# iND83213A register map
Vendor: Indiemicro; Series: Rugby; File version: 1.0
High performance IC
CPU: CM0 r0p1, selectable endian, no MPU, no FPU, 4 interrupt priority bits
Registers are 32-bit, read-write, no defined reset value unless marked. A register's access mark holds for its fields unless they carry their own. Offsets are from the block's base; lines under a group give offsets from that group; [hi:lo] are bit positions; {n}, {i} and the like mark numbered series; 'fields as' and 'values as' point back to an identical list; <NAME> marks a mode.

## Memory map
0x50000000 CRGA size 0x40 — Clock & Reset Generator
0x50000040 PMUA size 0x20 — Power Management Unit
0x50000060 EVTHOLD size 0x20 — Event Hold Control
0x50000080 BTE size 0x80 — Block Transfer Engine registers
0x50010100 WICA size 0x100 — WakeUp Interrupt Controller
0x50010200 WDTA size 0x100 — Watchdog Timer Registers
0x50010300 LINS size 0x100 — LIN slave interface registers
0x50010400 LINM size 0x100 — LIN master interface registers
0x50010500 BUCK_INF size 0x100 — BUCK Interface Registers
0x50010600 SAR_CTRL size 0x100 — SAR ADC Interface registers
0x50010700 SPI size 0x100 — SPIM Interface registers
0x50010800 UART size 0x100 — UART Interface registers
0x50010900 PWM_AUX size 0x100 — Control (and status) registers for the pulse width modulation waveform generator.
0x50011000 PWM size 0x1000 — Control (and status) registers for the pulse width modulation waveform generator.
0x50012000 IOCTRLA size 0x1000 — I/O configuration and DFT pin control
0x50013000 SYSCTRLA size 0x1000 — System configuration and retention memory
0x50014000 GPIO size 0x1000 — GPIO bit control and configuration
0x50015000 PMUAPRE5V size 0x1000 — Power Management Unit of 5V domain
0x50020000 TIMER0 size 0x8 — General purpose timer 0 registers
0x50020008 TIMER1 size 0x8 — General purpose timer 1 registers
0x50020010 TIMER2 size 0x8 — General purpose timer 2 registers
0x50020018 WDT1 size 0x8 — The watchdog timer that is local to VERNE MCU
0x50020020 FLASH size 0x40 — FLASH Memory registers

## EVTHOLD — Event Hold Control
Base 0x50000060; register names take the prefix EVTHOLD_
0x00 HOLD
  [0] HOLD wo — Hold. Set to prevent serialisation of new non-wakeup events in prepartion for hibernate mode. At the point of becoming set, a request to send the lullaby interrupt is automatically generated. The lullaby handler can then safely assert the PMUA->CTRL.HIBERNATE bit in order to put the device into hibernate mode.

## BTE — Block Transfer Engine registers
Base 0x50000080; register names take the prefix BTE_
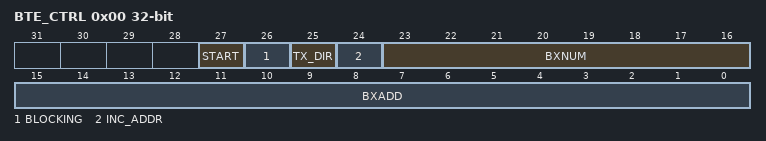
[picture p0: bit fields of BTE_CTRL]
0x00 BTE_CTRL — BTE Control Register
  [27] START — An operation is initiated when this bit is set. The bit auto-clears when the block is complete.
  [26] BLOCKING — If set then the block transfer has priority over the MCU. If the MCU tries to use the bus, it will stall until the block transfer is complete. If not set, then the MCU waits only until the remainder of the current word completes and then waits until the bus is idle again before continuing.
  [25] TX_DIR — Transfer direction. If set then SRAM->ASIC otherwise ASIC->SRAM
  [24] INC_ADDR — if set then ASIC die address increments at the end of each transfer. Set to zero if the peripheral is a FIFO.
  [23:16] BXNUM — Number of 32-bit words to transfer.
  [15:0] BXADD — Address of the ASIC die (LSB). This is the lower 16 bits of the ASIC die address. The MSBs are 0x5001.
0x04 BTE_SRAM_ADDR — BTE SRAM Address Register
  [15:0] BXSRAMADDR — Address of the SRAM (LSB). This is the lower 16 bits of the SRAM address. The MSBs are 0x2000.

## WICA — WakeUp Interrupt Controller
Base 0x50010100; register names take the prefix WICA_
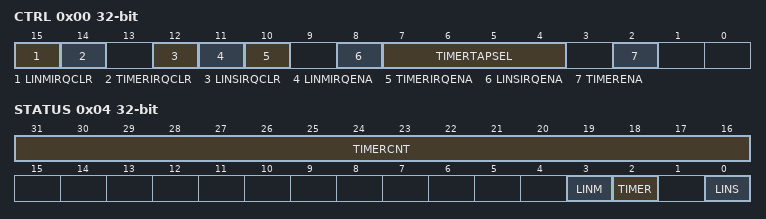
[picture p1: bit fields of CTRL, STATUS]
0x00 CTRL — Wakeup Control Register
  [15] LINMIRQCLR wo — clear the wulin_irq. writting a '1 to this register will clear the wulins_irq
  [14] TIMERIRQCLR wo — clear the wutimer_irq. writting a '1 to this register will clear the wutimer_irq
  [12] LINSIRQCLR wo — clear the wulin_irq. writting a '1 to this register will clear the wulins_irq
  [11] LINMIRQENA — LIN Master Wakeup Interrupt Enable. if set, wulinm_irq is asserted if a wakeup signal is detected on the LIN_OUT bus
  [10] TIMERIRQENA — Timer Wakeup Interrupt Enable. if set, wutimer_irq is asserted if wakeup timer matches the tapsel
  [8] LINSIRQENA — LIN Slave Wakeup Interrupt Enable. if set, wulin_irq is asserted if a wakeup signal is detected on the LIN_IN bus
  [7:4] TIMERTAPSEL — WakeUp Timer Tap Select. Wakeup Time = 2^(WUT_TAPSEL) x Tlfclk(62.5us)
  [2] TIMERENA — Wakeup Timer Enable. it enables the wakeup timer
0x04 STATUS — Wakeup Status Register
  [31:16] TIMERCNT ro — Wakeup Timer Counter Value. Counter Value of the Wakeup Timer
  [3] LINM ro — LIN Master Wakeup Status. This gets set if a wakeup signal is detected on the LIN_OUT bus when LINM SLEEP bit is set. CLRIRQ clears this Register
  [2] TIMER ro — Wakeup Timer Status. This gets set if a wakeup timer is enabled and the count matches the tapsel setting during hibernate, CLRIRQ clears this Register
  [0] LINS ro — LIN Slave Wakeup Status. This gets set if a wakeup signal is detected on the LIN_IN bus when LINS SLEEP bit is set. CLRIRQ clears this Register
